# M55M1 register map
File version: 1.0
Registers are 32-bit, read-write, reset 0x0 unless marked. A register's access mark holds for its fields unless they carry their own. Offsets are from the block's base; [hi:lo] are bit positions; {n}, {i} and the like mark numbered series; 'fields as' and 'values as' point back to an identical list.

## GDMA (part 1 of 2) — GDMA Register Map
Base 0x04004000
0x00 GDMA_SCFG_CHSEC0 — GDMA Secure Configuration Channel Security Mapping Register 0
  [31:0] SCFGCHSEC0 — Secure Configuration Channel Security Mapping for Channel 0 to 31. When [i] set to '1', CH is Non-secure world, else Secure world. The NUM_CHANNELS parameter limits this field, unused bits are RAZWI. Value for bit[i] can only be changed if the selected channel is not enabled, so reading back the register content is needed to check the success of the change. Note:The field is RAZ/WI when the following condition is False: SECEXT_PRESENT
0x08 GDMA_SCFG_TRIGINSEC0 — GDMA Secure Configuration Trigger Input Security Mapping Register 0
  [31:0] SCFGTRIGINSEC0 — Secure Configuration Channel Security Mapping for Channel 0 to 31. When [i] set to '1', CH is Non-secure world, else Secure world. The NUM_CHANNELS parameter limits this field, unused bits are RAZWI. Value for bit[i] can only be changed if the selected channel is not enabled, so reading back the register content is needed to check the success of the change. Note:The field is RAZ/WI when the following condition is False: SECEXT_PRESENT
0x28 GDMA_SCFG_TRIGOUTSEC0 — GDMA Secure Configuration Trigger Output Security Mapping Register 0
  [31:0] SCFGTRIGOUTSEC0 — Secure Configuration Tigger Output Security Mapping. When [i] set to '1', Trigger Output is Non-secure world, else Secure world. The NUM_TRIGGER_OUT parameter limits this field, unused bits are RAZWI. Value for bit[i] can only be changed if the trigger output port is not in use, so reading back the register content is needed to check the success of the change. The field is RAZ/WI when the following condition is False: SECEXT_PRESENT (1) (NUM_TRIGGER_OUT 0)
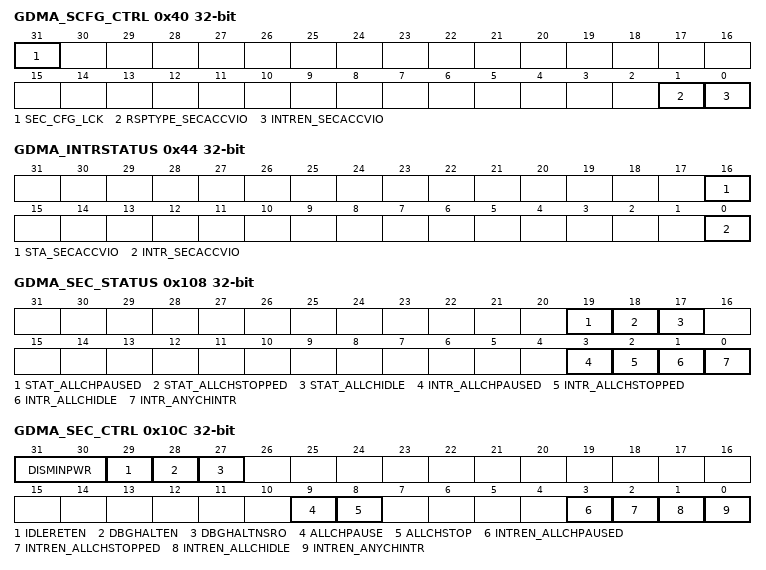
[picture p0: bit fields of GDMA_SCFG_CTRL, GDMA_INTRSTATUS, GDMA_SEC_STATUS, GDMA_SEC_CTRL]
0x40 GDMA_SCFG_CTRL — GDMA Secure Configuration Control
  [31] SEC_CFG_LCK — Security Configuration Lock. When set to '1', only SCFG.STAT_SECACCVIO can be cleared, all other register fields in this block become read-only. Once set to '1', this field can only be set back to '0' by reset. The field is RAZ/WI when the following condition is False: SECEXT_PRESENT
  [1] RSPTYPE_SECACCVIO — Secure Access Violation response type configuration. Note: The field is RAZ/WI when the following condition is False: SECEXT_PRESENT
    0=RAZWI; 1=Bus error
  [0] INTREN_SECACCVIO — Secure Access Violation Interrupt Enable. Note: The field is RAZ/WI when the following condition is False: SECEXT_PRESENT
    0=No interrupt; 1=Interrupt raised for security violation
0x44 GDMA_INTRSTATUS — GDMA Secure Configuration Interrupt Status
  [16] STA_SECACCVIO — Secure Access Violation Status. Set to '1' when a security violation occurred. Write '1' to clear. Note: The field is RAZ/WI when the following condition is False: SECEXT_PRESENT
  [0] INTR_SECACCVIO — Secure Access Violation Interrupt Status. Note: The field is RAZ/WI when the following condition is False: SECEXT_PRESENT
    0=Cleared automatically when STAT_SECACCVIO is cleared; 1=When SCFG.STAT_SECACCVIO is asserted and SCFG.INTREN_SECACCVIO = 1
0x100 GDMA_SEC_CHINTRSTATUS0 — GDMA Secure Channel Interrupt Status Register 0
  [31:0] CHINTRSTATUS0 — Secure Channel Interrupt flags for Channel 0 to 31. Collated Secure Channel Interrupt flags for channel 0 to Channel 31. Limited by NUM_CHANNELS, all unimplemented bits are reserved. The field is RAZ/WI when the following condition is False: SECEXT_PRESENT
0x108 GDMA_SEC_STATUS — GDMA Secure Status Register
  [19] STAT_ALLCHPAUSED — All Secure Channel Paused Status. Note: The field is RAZ/WI when the following condition is False: SECEXT_PRESEN
    0=Cleared by writing '1' to this bit which results in all secure channels to resume their operation. The ALLCHPAUSE request is also cleared when this bit is cleared; 1=Whenever all Secure DMA channel is in paused or inactive state and the ALLCHPAUSE request is active. Not set when channels reach the paused state for other reasons. All Secure channels are forced to an immediate pause until ALLCHPAUSE request is asserted even if they were enabled after the request
  [18] STAT_ALLCHSTOPPED — All Secure Channel Stopped Status. Note: The field is RAZ/WI when the following condition is False: SECEXT_PRESENT
    0=Cleared by writing '1' to this bit. The ALLCHSTOP request is also cleared when this bit is cleared; 1=Whenever all Secure DMA channels are in stopped or inactive state and the ALLCHSTOP request is active. Not set when channels reach the stopped state for other reasons. All Secure channels are forced to an immediate stopped state until ALLCHSTOP request is asserted even if they were enabled after the request
  [17] STAT_ALLCHIDLE — All Secure Channel Idle Status. Note: The field is RAZ/WI when the following condition is False: SECEXT_PRESEN
    0=Cleared by writing '1' to this bit; 1=Whenever all Secure DMA channel is in idle state after at least one channel was running
  [3] INTR_ALLCHPAUSED — All Secure Channel Paused Interrupt Status. Note: The field is RAZ/WI when the following condition is False: SECEXT_PRESENT
    0=Cleared automatically when STAT_ALLCHPAUSED is cleared; 1=When SECCTRL.STAT_ALLCHPAUSED is asserted and SECCTRL.INTREN_ALLCHPAUSED = 1
  [2] INTR_ALLCHSTOPPED — All Secure Channel Stopped Interrupt Status. Note: The field is RAZ/WI when the following condition is False: SECEXT_PRESENT
    0=Cleared automatically when STAT_ALLCHSTOPPED is cleared; 1=When SECCTRL.STAT_ALLCHSTOPPED is asserted and SECCTRL.INTREN_ALLCHSTOPPED = 1
  [1] INTR_ALLCHIDLE — All Secure Channel Idle Interrupt Status. Note: The field is RAZ/WI when the following condition is False: SECEXT_PRESENT
    0=Cleared automatically when STAT_ALLCHIDLE is cleared; 1=When SECCTRL.STAT_ALLCHIDLE is asserted and SECCTRL.INTREN_ALLCHIDLE = 1
  [0] INTR_ANYCHINTR — Combined Secure Channel Interrupt Flag. Note: The field is RAZ/WI when the following condition is False: SECEXT_PRESEN
    0=Cleared automatically when the source of the channel interrupt is cleared; 1=When any Secure channel has an interrupt request in CHINTRSTATUS0 and SECCTRL.INTREN_ANYCHINTR = 1
0x10C GDMA_SEC_CTRL — GDMA Secure Control Register
  [31:30] DISMINPWR — Minimum Power state of the DMAC when at least one secure channel is present. Note: The field is RAZ/WI when the following condition is False: SECEXT_PRESEN
    0=OFF; 1=Retention; 2=ON
  [29] IDLERETEN — Idle Channel Retention Enable. Allows retention for Secure channels that are enabled and waiting for an event in IDLE state. Note: The field is RAZ/WI when the following condition is False: SECEXT_PRESENT (1)
    0=Disabled; 1=Enabled
  [28] DBGHALTEN — Debug Halt Enabled. Note: The field is RAZ/WI when the following condition is False: SECEXT_PRESENT
    0=The DMA ignores the halt request from an external debugger. Clearing this bit while halt is ongoing results in continuing the operation; 1=The debugger request to halt the DMA is allowed for all channels. This field is common for non-secure and secure side of the DMA, but control can be limited by the SEC_CTRL.DBGHALTNSRO register field
  [27] DBGHALTNSRO — Debug Halt Enable Non-Secure Read Only. Note: The field is RAZ/WI when the following condition is False: SECEXT_PRESENT
    0=NSEC_CTRL.DBGHALTEN has read-write access. This register allows the secure SW to limit the non-secure SW adjusting the common DBGHALTEN register bit; 1=The NSEC_CTRL.DBGHALTEN register becomes read-only
  [9] ALLCHPAUSE — Secure All Channel Pause Request. Note: The field is RAZ/WI when the following condition is False: SECEXT_PRESENT
    0=Cleared automatically when the STAT_ALLCHPAUSED status flag is cleared; 1=All Secure channels get a pause request. Stays asserted until the channels are paused and the STAT_ALLCHPAUSED status flag is set
  [8] ALLCHSTOP — Secure All Channel Stop Request. Note: The field is RAZ/ WI when the following condition is False: SECEXT_PRESENT
    0=Cleared automatically when the STAT_ALLCHSTOPPED status flag is cleared; 1=All Secure channels get a stop request. Stays asserted until the STAT_ALLCHSTOPPED status flag is set
  [3] INTREN_ALLCHPAUSED — All Secure Channel Paused Interrupt Enable. The field is RAZ/WI when the following condition is False: SECEXT_PRESENT
  [2] INTREN_ALLCHSTOPPED — All Secure Channels Stopped Interrupt Enable. The field is RAZ/WI when the following condition is False: SECEXT_PRESENT
  [1] INTREN_ALLCHIDLE — All Secure Channel Idle Interrupt Enable. The field is RAZ/WI when the following condition is False: SECEXT_PRESENT
  [0] INTREN_ANYCHINTR — Combined Secure Channel Interrupt Enable. The field is RAZ/WI when the following condition is False: SECEXT_PRESENT
0x114 GDMA_SEC_CHPTR — GDMA Secure Channel Pointer
  [5:0] CHPTR — Secure Channel Pointer. Selects which channel settings can be adjusted by the following registers. The field is RAZ/WI when the following condition is False: SECEXT_PRESENT
0x1F0 GDMA_SEC_STATUSPTR — GDMA Secure Unit Status Pointer Register
  [3:0] SECSTATUSPTR — Secure DMA Unit Status Pointer. Secure DMA Unit status pointer used to select which status value to view using STATUSVALUE register. Pointer values are: Note: The field is RAZ/WI when the following condition is False: SECEXT_PRESENT
    0=Channel Enabled Status for channel numbers [31:0]; 2=Channel Stopped Status for channel numbers [31:0]; 4=Channel Paused Status for channel numbers [31:0]
0x1F4 GDMA_SEC_STATUSVAL ro — GDMA Secure Unit Status Value Register
  [31:0] SECSTATUSVAL — Secure DMA Unit status value. Can be used for reading internal status values of the DMA Unit for debug purposes. Values shown here are dependent on STATUSPTR. Note that inputs are masked by security mapping before being presented here. This means that only status values mapped to Secure world are visible as non-Zero values. All unimplemented bits are RAZWI. The field is RAZ/WI when the following condition is False: SECEXT_PRESENT
0x1F8 GDMA_SEC_SIGNALPTR — GDMA Secure Unit Signal Pointer
  [3:0] SECSIGNALPTR — Secure DMA Unit Signal Pointer. Secure DMA Unit signal pointer used to select which inputs to view using SIGNALVAL register. Pointer values, x, are: Note: The field is RAZ/WI when the following condition is False: SECEXT_PRESENT
0x1FC GDMA_SEC_SIGNALVAL — GDMA Secure Unit Signal Value Register
  [31:0] SECSIGNALVAL — Secure DMA Unit signal status. Can be used for reading signal values of triggers and GPOs for debug. Values shown here are dependent on SIGNALPTR. Note that inputs are masked by security mapping before being presented here. This means that only signal values mapped to Secure world are visible as non-zero values. Writing to this register has the following effect: Writing '1' to a Trigger Input Request that are not selected by any DMA channel will cause a deny response for it. This can attempt to clear an unwanted trigger input. Writing '1' to any Trigger Output Acknowledges status, GPO value and all Trigger Input Request selected by any DMA channel is ignored. All unimplemented bits are RAZWI. Note: The field is RAZ/WI when the following condition is False: SECEXT_PRESENT
0x200 GDMA_NSEC_CHINTRSTATUS0 — GDMA Non-Secure Channel Interrupt Status Register 0
  [31:0] CHINTRSTATUS0 — Channel Interrupt Status. Collated Non-Secure Channel Interrupt flags for channel 0 to channel 31. Limited by NUM_CHANNELS, all unimplemented bits are reserved
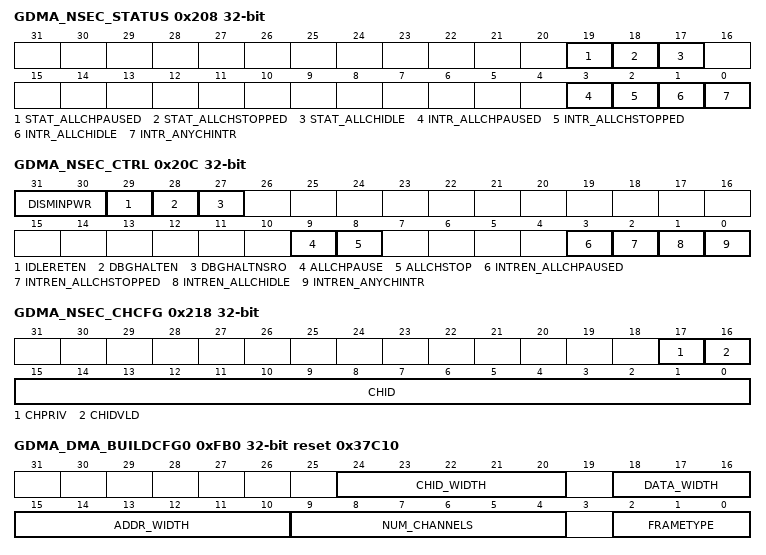
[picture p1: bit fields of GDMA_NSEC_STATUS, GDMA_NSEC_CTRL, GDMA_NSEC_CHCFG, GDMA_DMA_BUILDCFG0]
0x208 GDMA_NSEC_STATUS — GDMA Non-Secure Status Register
  [19] STAT_ALLCHPAUSED — All Non-Secure Channel Paused Status
    0=The ALLCHPAUSE request is also cleared when this bit is cleared; 1=Whenever all Non-secure DMA channel is in paused or inactive state and the ALLCHPAUSE request is active. Not set when channels reach the paused state for other reasons. All Non-secure channels are forced to an immediate pause until ALLCHPAUSE request is asserted even if they were enabled after the request. Cleared by writing '1' to this bit which results in all Nonsecure channels to resume their operation
  [18] STAT_ALLCHSTOPPED — All Non-Secure Channel Stopped Status
    0=The ALLCHSTOP request is also cleared when this bit is cleared; 1=Whenever all Non-secure DMA channels are in stopped or inactive state and the ALLCHSTOP request is active. Not set when channels reach the stopped state for other reasons. All Non-secure channels are forced to an immediate stopped state until ALLCHSTOP request is asserted even if they were enabled after the request. Cleared by writing '1' to this bit
  [17] STAT_ALLCHIDLE — All Non-Secure Channel Idle Status
    0=Cleared by writing '1' to this bit; 1=Whenever all Non-secure DMA channel is in idle state after at least one channel was running
  [3] INTR_ALLCHPAUSED — All Non-Secure Channel Paused Interrupt Status
    0=Cleared automatically when STAT_ALLCHPAUSED is cleared; 1=When NSECCTRL.STAT_ALLCHPAUSED is asserted and NSECCTRL.INTREN_ALLCHPAUSED = 1
  [2] INTR_ALLCHSTOPPED — All Non-Secure Channel Stopped Interrupt Status
    0=Cleared automatically when STAT_ALLCHSTOPPED is cleared; 1=When NSECCTRL.STAT_ALLCHSTOPPED is asserted and NSECCTRL.INTREN_ALLCHSTOPPED = 1
  [1] INTR_ALLCHIDLE — All Non-Secure Channel Idle Interrupt Status
    0=Cleared automatically when STAT_ALLCHIDLE is cleared; 1=When NSECCTRL.STAT_ALLCHIDLE is asserted and NSECCTRL.INTREN_ALLCHIDLE = 1
  [0] INTR_ANYCHINTR — Combined Non-Secure Channel Interrupt Flag
    0=Cleared automatically when the source of the channel interrupt is cleared; 1=When any Non-secure channel has an interrupt request in CHINTRSTATUS0 and NSECCTRL.INTREN_ANYCHINTR = 1
0x20C GDMA_NSEC_CTRL — GDMA Non-Secure Control Register
  [31:30] DISMINPWR — Minimum Power state of the DMAC when at least one non-secure channel is present
    0=OFF; 1=Retention; 2=ON
  [29] IDLERETEN — Idle Channel Retention Enable. Allows retention for non-secure channels that are enabled and waiting for an event in IDLE state.
    0=Disabled; 1=Enabled
  [28] DBGHALTEN — Debug Halt Enabled
    0=The DMA ignores the halt request from an external debugger. Clearing this bit while halt is ongoing results in continuing the operation; 1=The debugger request to halt the DMA is allowed. This field is common for non-secure and secure side of the DMA, but access to this register is limited by the DBGHALTNSRO register field
  [27] DBGHALTNSRO — Debug Halt Enable Non-Secure Read Only. Note: This register is read-only for the non-secure SW
    0=NSEC_CTRL.DBGHALTEN has read-write access; 1=The NSEC_CTRL.DBGHALTEN register becomes read-only
  [9] ALLCHPAUSE — Non-Secure All Channel Pause Request
    0=Cleared automatically when the STAT_ALLCHPAUSED status flag is cleared; 1=All Non-secure channels get a pause request. Stays asserted until the channels are paused and the STAT_ALLCHPAUSED status flag is set
  [8] ALLCHSTOP — Non-Secure All Channel Stop Request
    0=Cleared automatically when the STAT_ALLCHSTOPPED status flag is cleared; 1=All Non-secure channels get a stop request. Stays asserted until the STAT_ALLCHSTOPPED status flag is set
  [3] INTREN_ALLCHPAUSED — All Non-Secure Channel Paused Interrupt Enable
  [2] INTREN_ALLCHSTOPPED — All Non-Secure Channels Stopped Interrupt Enable
  [1] INTREN_ALLCHIDLE — All Non-Secure Channel Idle Interrupt Enable
  [0] INTREN_ANYCHINTR — Combined Non-Secure Channel Interrupt Enable
0x214 GDMA_NSEC_CHPTR — GDMA Non-Secure Channel Pointer
  [5:0] CHPTR — Non-Secure Channel Pointer. Selects which channel settings can be adjusted by the following registers
0x218 GDMA_NSEC_CHCFG — GDMA Non-Secure Channel Configuration Register
  [17] CHPRIV — Non-Secure Channel Privilege Enable. NSECCHPTR selects the channel.
    0=The channel is only allowed to send unprivileged transfers and the channel registers can be accessed by both privileged and unprivileged register accesses; 1=It allows the channel to send transfers marked as Privileged only. The configuration registers of the selected channel are also given privileged only access rights
  [16] CHIDVLD — Non-Secure Channel ID valid. NSECCHPTR selects the channel. Set to '1' to drive the channel ID value in CHID for all the transfers by the selected channel. The field is RAZ/WI when the following condition is False: CHID_WIDTH 0
  [15:0] CHID — Non-Secure Channel ID value. NSECCHPTR selects the channel ID value to be read or written via this register. CHID_WIDTH limits this field, unused bits are RAZWI. The field is RAZ/WI when the following condition is False: CHID_WIDTH 0
0x2F0 GDMA_NSEC_STATUSPTR — GDMA Non-Secure Unit Status Pointer Register
  [3:0] NSECSTATUSPTR — Non-Secure DMA Unit status pointer. Used to select which status value to view using STATUSVALUE register. Pointer values are:
    values as GDMA_SEC_STATUSPTR.SECSTATUSPTR
0x2F4 GDMA_NSEC_STATUSVAL ro — GDMA Non-Secure Unit Status Value Register
  [31:0] NSECSTATUSVAL — Non-Secure DMA Unit status value. Can be used for reading internal status values of the DMA Unit for debug purposes. Values shown here are dependent on STATUSPTR. Note that inputs are masked by security mapping before being presented here. This means that only status values mapped to Non-secure world are visible as non-Zero values. All unimplemented bits are RAZWI.
0x2F8 GDMA_NSEC_SIGNALPTR — GDMA Non-Secure Unit Signal Pointer
  [3:0] NSECSINGALPTR — Non-Secure DMA Unit signal pointer. Used to select which inputs or outputs to view using SIGNALVAL register. Pointer values, x, are:
    {v}=Trigger Input Requests [31+32x : 32x] (v=0..7); 8=Trigger output Acknowledges [31+32(x-8) : 32(x-8)]; 9=Trigger output Acknowledges [31+32(x-8) : 32(x-8)]; 10=GPO output value [31+32(x-10) : 32(x-10)], only present when HAS_GPOSEL is set; 11=GPO output value [31+32(x-10) : 32(x-10)], only present when HAS_GPOSEL is set
0x2FC GDMA_NSEC_SIGNALVAL — GDMA Non-Secure Unit Signal Value Register
  [31:0] NSECSIGNALVAL — Non-Secure DMA Unit signal status. Can be used for reading signal values of triggers and GPOs for debug. Values shown here are dependent on SIGNALPTR. Note that inputs are masked by security mapping before being presented here. This means that only signals mapped to Non-secure world are visible as non-zero values. Writing to this register has the following effect: Writing '1' to a Non-secure Trigger Input Request that are not selected by any DMA channel will cause a deny response for it. This can attempt to clear an unwanted trigger input. Writing '1' to any Trigger Output Acknowledges status, GPO status and all Trigger Input Request already selected by any DMA channel is ignored. All unimplemented bits are RAZWI.
0xFB0 GDMA_DMA_BUILDCFG0 ro reset 0x37C10 — GDMA DMA Build Configuration Register 0
  [24:20] CHID_WIDTH — Channel ID Width
    0=means CHID is not present
  [18:16] DATA_WIDTH
    0=8-bit; 1=16-bit; 2=32-bit; 3=64-bit; 4=128-bit; 5=256-bit; 6=512-bit; 7=1024-bit
  [15:10] ADDR_WIDTH — Address Width
  [9:4] NUM_CHANNELS — Number of Channels. Number of Channels + 1 supported by the DMAC
  [2:0] FRAMETYPE — Register Frame Type. Note: Each frame replicates the Information fields.
    0=Combined Frame; 1=Security Configuration Frame; 2=Secure Control Frame, or if TrustZone not implemented, Control Frame; 3=Non-Secure Control Frame; 4=DMA Channel Frame
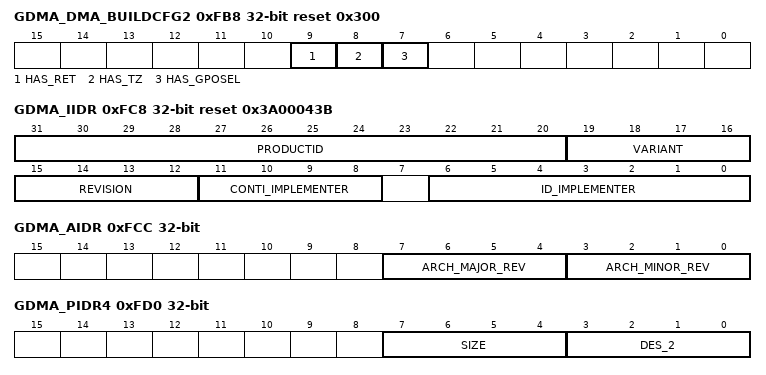
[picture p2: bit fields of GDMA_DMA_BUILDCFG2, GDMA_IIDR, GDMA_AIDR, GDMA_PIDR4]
0xFB8 GDMA_DMA_BUILDCFG2 ro reset 0x300 — GDMA DMA Build Configuration Register 2
  [9] HAS_RET — Has Retention Support
    0=No retention support; 1=Has retention support
  [8] HAS_TZ — Has TrustZone Support
    0=No TrustZone support; 1=Has TrustZone support
  [7] HAS_GPOSEL — Has Shared and hence Selectable GPO Support
    0=No GPO support; 1=Has shared and selectable GPO support
0xFC8 GDMA_IIDR ro reset 0x3A00043B — GDMA Implementation Identification Register
  [31:20] PRODUCTID — Indicates the product ID
  [19:16] VARIANT — Indicates the major revision, or variant, of the product rxpy identifier
  [15:12] REVISION — Indicates the minor revision of the product rxpy identifier
  [11:8] CONTI_IMPLEMENTER — JEP106 Continuation Code of Implementer. JEP106 continuation code of implementer. Note: For Arm this field (bit [11:0]) reads as 0x43B. It indicates the JEP106 code.
  [6:0] ID_IMPLEMENTER — JEP106 Identify Code of Implementer. JEP106 identity code of implementer. Note: For Arm this field reads as 0x43B. It indicates the JEP106 code.
0xFCC GDMA_AIDR ro — GDMA Architecture Identification Register
  [7:4] ARCH_MAJOR_REV — Architecture Major Revision
  [3:0] ARCH_MINOR_REV — Architecture Minor Revision
0xFD0 GDMA_PIDR4 ro — GDMA Peripheral ID4 Register
  [7:4] SIZE — 4 Kbytes Count - the Number of 4K Pages Used
    0=4K; 1=8K; 2=16K; 3=32K
  [3:0] DES_2 — JEP106 Continuation Code
0xFE0 GDMA_PIDR0 ro — GDMA Peripheral ID0 Register
  [7:0] PART_0 — Part Number [7:0]
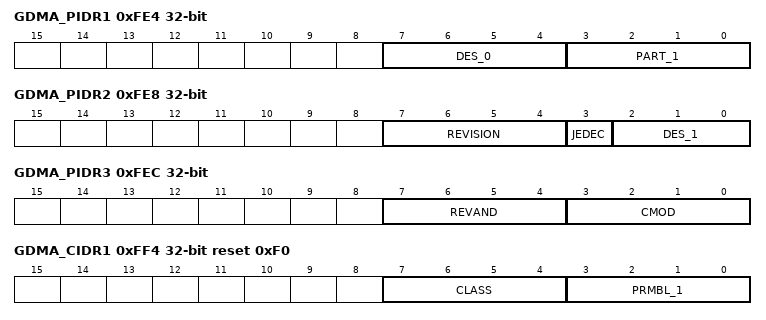
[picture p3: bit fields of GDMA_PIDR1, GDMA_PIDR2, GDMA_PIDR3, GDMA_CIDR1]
0xFE4 GDMA_PIDR1 ro — GDMA Peripheral ID1 Register
  [7:4] DES_0 — JEP106 Identify Code [3:0]
  [3:0] PART_1 — Part Number [11:8]
0xFE8 GDMA_PIDR2 ro — GDMA Peripheral ID2 Register
  [7:4] REVISION — Revision Code
  [3] JEDEC
  [2:0] DES_1 — JEP106 Identify Code [6:4]
0xFEC GDMA_PIDR3 ro — GDMA Peripheral ID3 Register
  [7:4] REVAND — Manufacturer revision number
  [3:0] CMOD — Customer Modified
0xFF0 GDMA_CIDR0 ro reset 0xD — GDMA Component ID0 Register
  [7:0] PRMBL_0 — Preamble
0xFF4 GDMA_CIDR1 ro reset 0xF0 — GDMA Component ID1 Register
  [7:4] CLASS — Component class
  [3:0] PRMBL_1 — Preamble
0xFF8 GDMA_CIDR2 ro reset 0x5 — GDMA Component ID2 Register
  [7:0] PRMBL_2 — Preamble
0xFFC GDMA_CIDR3 ro reset 0xB1 — GDMA Component ID3 Register
  [7:0] PRMBL_3 — Preamble
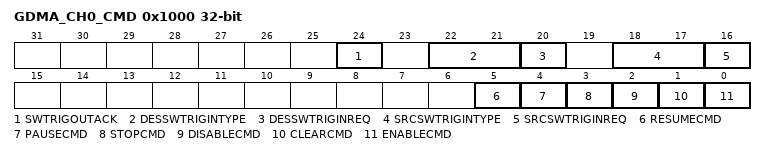
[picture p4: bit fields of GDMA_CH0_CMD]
0x1000 GDMA_CH0_CMD — GDMA Channel Command Register
  [24] SWTRIGOUTACK — Software Generated Trigger Output Acknowledge. Write '1' to acknowledge a Trigger Output request from the DMA. Once set to '1', this will remain high until the DMA Trigger Output is raised (either on the trigger output signal or as an interrupt) and the acknowledge is accepted. Note: When the channel is not enabled, write to this register is ignored.
  [22:21] DESSWTRIGINTYPE — Software Generated Destination Trigger Input Request Type. Selects the trigger request type for the destination trigger input when the SW triggers the DESSWTRIGINREQ bit. Note: This field cannot be changed while the DESSWTRIGINREQ bit is set. The field is RAZ/WI when the following condition is False: (1) (NUM_TRIGGER_IN 0)
    0=Single request; 1=Last single request; 2=Block request; 3=Last block request
  [20] DESSWTRIGINREQ — Software Generated Destination Trigger Input Request. Write to '1' to create a SW trigger request to the DMA with the specified type in the DESSWTRIGINTYPE register. Once set to '1', this will remain high until the DMA is accepted the trigger and will return this to '0'. It will also be cleared automatically if the current command is completed without expecting another trigger event. Note: When the channel is not enabled, write to this register is ignored
  [18:17] SRCSWTRIGINTYPE — Software Generated Source Trigger Input Request Type. Selects the trigger request type for the source trigger input when the SW triggers the SRCSWTRIGINREQ bit. Note: This field cannot be changed while the SRCSWTRIGINREQ bit is set. The field is RAZ/WI when the following condition is False: (1) (NUM_TRIGGER_IN 0)
    values as DESSWTRIGINTYPE
  [16] SRCSWTRIGINREQ — Software Generated Source Trigger Input Request. Write to '1' to create a SW trigger request to the DMA with the specified type in the SRCSWTRIGINTYPE register. Once set to '1', this will remain high until the DMA accepted the trigger and will return this to '0'. It will also be cleared automatically if the current command is completed without expecting another trigger event. Note: When the channel is not enabled, write to this register is ignored.
  [5] RESUMECMD — Resume Current DMA Operation. Writing this bit to '1' means that the DMAC can continue the operation of a paused channel. Can be set to '1' when the PAUSECMD or a STAT_DONE assertion with DONEPAUSEEN set HIGH results in pausing the current DMA channel operation indicated by the STAT_PAUSED and STAT_RESUMEWAIT bits. Otherwise, writes to this bit are ignored.
  [4] PAUSECMD — Pause Current DMA Operation. Once set to '1' the status cannot change until the DMA operation reached the paused state indicated by the STAT_PAUSED and STAT_RESUMEWAIT bits. The bit can be set by SW by writing it to '1', the current active DMA operation will be paused as soon as possible, but the ENABLECMD bit will remain HIGH to show that the operation is still active. Cleared automatically when STAT_RESUMEWAIT is set and the RESUMECMD bit is written to '1', meaning that the SW continues the operation of the channel. Note: each DMA channel can have other sources of a pause request and this field will not reflect the state of the other sources. When set at the same time as ENABLECMD or when the channel is not enabled then write to this register is ignored.
  [3] STOPCMD — Stop Current DMA Operation. Once set to '1', his will remain high until the DMA channel is stopped cleanly. Then this will return to '0' and ENABLECMD is also cleared. When set at the same time as ENABLECMD or when the channel is not enabled then write to this register is ignored. Note that each DMA channel can have other sources of a stop request and this field will not reflect the state of the other sources.
  [2] DISABLECMD — Disable DMA Operation at the end of the current DMA command operation. Once set to '1', this field will stay high and the current DMA command will be allowed to complete, but the DMA will not fetch the next linked command or will it auto-restart the DMA command even if they are set. Once the DMA has stopped, it will return to '0' and ENABLECMD is also cleared. When set at the same time as ENABLECMD or when the channel is not enabled then write to this register is ignored
  [1] CLEARCMD — DMA Clear command. When set to '1', it will remain high until all DMA channel registers and any internal queues and buffers are cleared, before returning to '0'. When set at the same time as ENABLECMD or while the DMA channel is already enabled, the clear will only occur after any ongoing DMA operation is either completed, stopped or disabled and the ENABLECMD bit is deasserted by the DMA.
  [0] ENABLECMD — Channel Enable. When set to '1', enables the channel to run its programmed task. When set to '1', it cannot be set back to zero, and this field will automatically clear to zero when a DMA process is completed. To force the DMA to stop prematurely, you must use CH_CMD.STOPCMD instead
